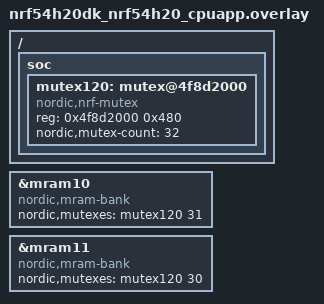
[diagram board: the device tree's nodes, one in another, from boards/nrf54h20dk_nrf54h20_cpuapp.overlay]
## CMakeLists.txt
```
#
# Copyright (c) 2026 Nordic Semiconductor ASA
#
# SPDX-License-Identifier: Apache-2.0
#

cmake_minimum_required(VERSION 3.20.0)

find_package(Zephyr REQUIRED HINTS $ENV{ZEPHYR_BASE})
project(nrf_mram_build)

target_sources(app PRIVATE src/main.c)
```

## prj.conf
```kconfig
CONFIG_FLASH=y
CONFIG_SOC_FLASH_NRF_MRAM=y
CONFIG_ASSERT=y

CONFIG_BOOT_BANNER=n
```

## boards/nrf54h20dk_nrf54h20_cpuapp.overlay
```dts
/*
 * Copyright (c) 2026 Nordic Semiconductor ASA
 *
 * SPDX-License-Identifier: Apache-2.0
 */

/* The nRF54H20 and nRF9280 devicetrees have no MRAM hardware mutex description yet;
 * add one so that the driver's mutex locking can be built on these SoCs.
 */
&mram10 {
	compatible = "nordic,mram-bank";
	nordic,mutexes = <&mutex120 31>;
};

&mram11 {
	compatible = "nordic,mram-bank";
	nordic,mutexes = <&mutex120 30>;
};

/ {
	soc {
		mutex120: mutex@4f8d2000 {
			compatible = "nordic,nrf-mutex";
			reg = <0x4f8d2000 0x480>;
			#mutex-cells = <1>;
			nordic,mutex-count = <32>;
			status = "okay";
		};
	};
};
```

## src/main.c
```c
/*
 * Copyright (c) 2026 Nordic Semiconductor ASA
 *
 * SPDX-License-Identifier: Apache-2.0
 */

#include <zephyr/kernel.h>

#if defined(CONFIG_RISCV_CORE_NORDIC_VPR)
BUILD_ASSERT(!IS_ENABLED(CONFIG_SOC_FLASH_NRF_MRAM),
	     "The MRAM flash driver must not be built for the VPR cores");
#endif

/* Build-only test: it just needs to compile and link the MRAM flash driver. */
int main(void)
{
	return 0;
}
```
